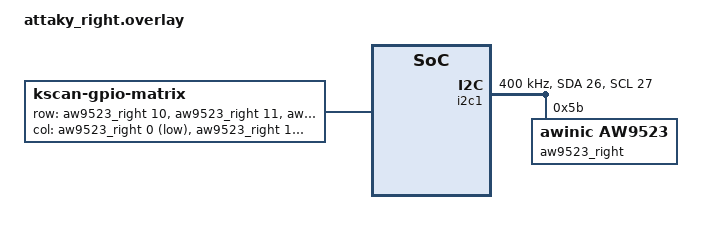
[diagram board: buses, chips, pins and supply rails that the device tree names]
#include <dt-bindings/zmk/matrix_transform.h>
#include <dt-bindings/gpio/gpio.h>

/ {
    compatible = "zmk,shield-attaky_right", "zmk,shield";

    chosen {
        zmk,kscan = &kscan;
    };

    // 定义并标记 kscan 节点（推荐方案 1）
    kscan: kscan {
        compatible = "zmk,kscan-gpio-matrix";
        label = "KSCAN";
        
        // 行：AW9523 P10-P14（输出）
        row-gpios = <&aw9523_right 10 GPIO_ACTIVE_HIGH>,
                    <&aw9523_right 11 GPIO_ACTIVE_HIGH>,
                    <&aw9523_right 12 GPIO_ACTIVE_HIGH>,
                    <&aw9523_right 13 GPIO_ACTIVE_HIGH>,
                    <&aw9523_right 14 GPIO_ACTIVE_HIGH>;
        
        // 列：AW9523 P00-P04（输入）
        col-gpios = <&aw9523_right 0 GPIO_ACTIVE_LOW>,
                    <&aw9523_right 1 GPIO_ACTIVE_LOW>,
                    <&aw9523_right 2 GPIO_ACTIVE_LOW>,
                    <&aw9523_right 3 GPIO_ACTIVE_LOW>,
                    <&aw9523_right 4 GPIO_ACTIVE_LOW>;
        
        debounce-press-ms = <5>;
        debounce-release-ms = <5>;
    };
};

// 配置 I2C1 并添加 AW9523
&i2c1 {
    status = "okay";
    #address-cells = <1>;
    #size-cells = <0>;
    sda-pin = <26>;
    scl-pin = <27>;
    clock-frequency = <400000>;

    aw9523_right: aw9523@5b {
        compatible = "awinic,aw9523";
        reg = <0x5B>;
        gpio-controller;
        #gpio-cells = <2>;
        awinic,mode = <0>;
    };
};
